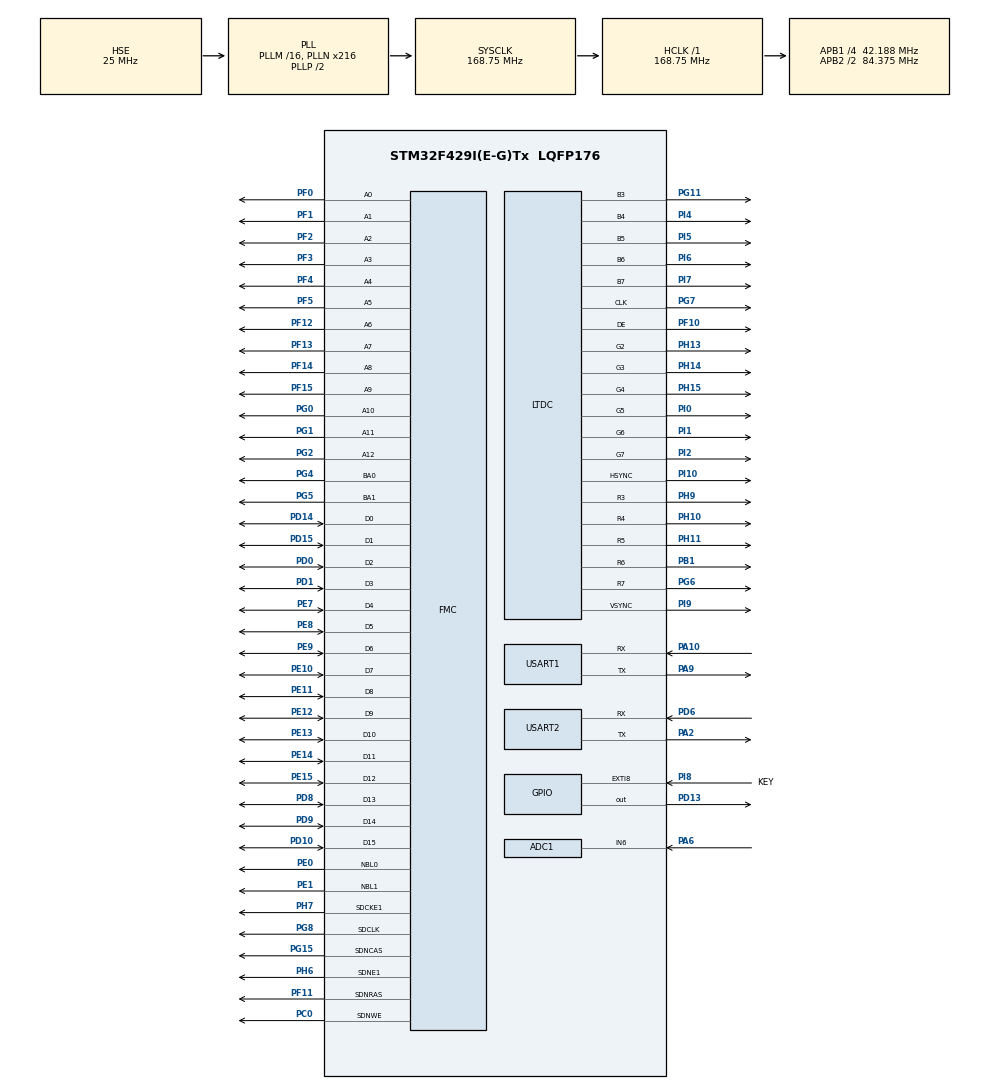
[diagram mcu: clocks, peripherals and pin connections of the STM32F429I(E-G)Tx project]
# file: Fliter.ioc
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ADC1.Channel-3\#ChannelRegularConversion=ADC_CHANNEL_6
ADC1.DMAContinuousRequests=ENABLE
ADC1.EOCSelection=ADC_EOC_SEQ_CONV
ADC1.ExternalTrigConv=ADC_EXTERNALTRIGCONV_T3_TRGO
ADC1.InjNumberOfConversion=0
ADC1.NbrOfConversion=1
ADC1.NbrOfConversionFlag=1
ADC1.Rank-3\#ChannelRegularConversion=1
ADC1.SamplingTime-3\#ChannelRegularConversion=ADC_SAMPLETIME_3CYCLES
ADC1.master=1
DMA2D.ColorMode=DMA2D_OUTPUT_RGB565
DMA2D.Mode=DMA2D_R2M
Dma.ADC1.0.Direction=DMA_PERIPH_TO_MEMORY
Dma.ADC1.0.FIFOMode=DMA_FIFOMODE_DISABLE
Dma.ADC1.0.Instance=DMA2_Stream0
Dma.ADC1.0.MemDataAlignment=DMA_MDATAALIGN_HALFWORD
Dma.ADC1.0.MemInc=DMA_MINC_ENABLE
Dma.ADC1.0.Mode=DMA_NORMAL
Dma.ADC1.0.PeriphDataAlignment=DMA_PDATAALIGN_HALFWORD
Dma.ADC1.0.PeriphInc=DMA_PINC_DISABLE
Dma.ADC1.0.Priority=DMA_PRIORITY_LOW
Dma.Request0=ADC1
FMC.CASLatency2=FMC_SDRAM_CAS_LATENCY_3
FMC.ColumnBitsNumber2=FMC_SDRAM_COLUMN_BITS_NUM_9
FMC.ExitSelfRefreshDelay2=7
FMC.LoadToActiveDelay2=2
FMC.RCDDelay2=2
FMC.RPDelay1=2
FMC.RPDelay2=2
FMC.ReadBurst1=FMC_SDRAM_RBURST_ENABLE
FMC.ReadBurst2=FMC_SDRAM_RBURST_ENABLE
FMC.ReadPipeDelay1=FMC_SDRAM_RPIPE_DELAY_1
FMC.ReadPipeDelay2=FMC_SDRAM_RPIPE_DELAY_1
FMC.RowCycleDelay1=7
FMC.RowCycleDelay2=7
FMC.SDClockPeriod1=FMC_SDRAM_CLOCK_PERIOD_2
FMC.SDClockPeriod2=FMC_SDRAM_CLOCK_PERIOD_2
FMC.SelfRefreshTime2=4
FMC.WriteRecoveryTime2=3
LTDC.ActiveH=272
LTDC.ActiveW=480
LTDC.Alpha_L0=255
LTDC.BlendingFactor1_L0=LTDC_BLENDING_FACTOR1_CA
LTDC.BlendingFactor1_L1=LTDC_BLENDING_FACTOR1_PAxCA
LTDC.BlendingFactor2_L0=LTDC_BLENDING_FACTOR2_CA
LTDC.BlendingFactor2_L1=LTDC_BLENDING_FACTOR2_PAxCA
LTDC.FBStartAdress_L0=0xD0000000
LTDC.FBStartAdress_L1=0xDD000000
LTDC.HBP=43
LTDC.HFP=8
LTDC.HSync=1
LTDC.ImageHeight_L0=272
LTDC.ImageHeight_L1=272
LTDC.ImageWidth_L0=480
LTDC.ImageWidth_L1=480
LTDC.Layers=0
LTDC.PixelFormat_L0=LTDC_PIXEL_FORMAT_RGB565
LTDC.VBP=12
LTDC.VFP=8
LTDC.VSync=1
LTDC.WindowX1_L0=480
LTDC.WindowX1_L1=480
LTDC.WindowY1_L0=272
LTDC.WindowY1_L1=272
Mcu.Family=STM32F4
Mcu.Name=STM32F429I(E-G)Tx
Mcu.Package=LQFP176
NVIC.DMA2D_IRQn=true\:0\:0\:false\:false\:true\:true\:true
NVIC.DMA2_Stream0_IRQn=true\:0\:0\:false\:false\:true\:true\:true
NVIC.EXTI9_5_IRQn=true\:0\:0\:false\:false\:true\:true\:true
NVIC.LTDC_IRQn=true\:0\:0\:false\:false\:true\:true\:true
NVIC.PriorityGroup=NVIC_PRIORITYGROUP_4
PA10.Mode=Asynchronous
PA10.Signal=USART1_RX
PA13.Mode=Serial_Wire
PA13.Signal=SYS_JTMS-SWDIO
PA14.Mode=Serial_Wire
PA14.Signal=SYS_JTCK-SWCLK
PA2.Mode=Asynchronous
PA2.Signal=USART2_TX
PA6.Signal=ADCx_IN6
PA9.Mode=Asynchronous
PA9.Signal=USART1_TX
PB1.GPIO_PuPd=GPIO_NOPULL
PB1.GPIO_Speed=GPIO_SPEED_FREQ_LOW
PB1.Mode=RGB565
PB1.Signal=LTDC_R6
PC0.Signal=FMC_SDNWE
PD0.Signal=FMC_D2_DA2
PD1.Signal=FMC_D3_DA3
PD10.Signal=FMC_D15_DA15
PD13.GPIO_PuPd=GPIO_PULLUP
PD13.PinState=GPIO_PIN_SET
PD13.Signal=GPIO_Output
PD14.Signal=FMC_D0_DA0
PD15.Signal=FMC_D1_DA1
PD6.Mode=Asynchronous
PD6.Signal=USART2_RX
PD8.Signal=FMC_D13_DA13
PD9.Signal=FMC_D14_DA14
PE0.Signal=FMC_NBL0
PE1.Signal=FMC_NBL1
PE10.Signal=FMC_D7_DA7
PE11.Signal=FMC_D8_DA8
PE12.Signal=FMC_D9_DA9
PE13.Signal=FMC_D10_DA10
PE14.Signal=FMC_D11_DA11
PE15.Signal=FMC_D12_DA12
PE7.Signal=FMC_D4_DA4
PE8.Signal=FMC_D5_DA5
PE9.Signal=FMC_D6_DA6
PF0.Signal=FMC_A0
PF1.Signal=FMC_A1
PF10.GPIO_PuPd=GPIO_NOPULL
PF10.GPIO_Speed=GPIO_SPEED_FREQ_LOW
PF10.Mode=RGB565
PF10.Signal=LTDC_DE
PF11.Signal=FMC_SDNRAS
PF12.Signal=FMC_A6
PF13.Signal=FMC_A7
PF14.Signal=FMC_A8
PF15.Signal=FMC_A9
PF2.Signal=FMC_A2
PF3.Signal=FMC_A3
PF4.Signal=FMC_A4
PF5.Signal=FMC_A5
PG0.Signal=FMC_A10
PG1.Signal=FMC_A11
PG11.GPIO_PuPd=GPIO_NOPULL
PG11.GPIO_Speed=GPIO_SPEED_FREQ_LOW
PG11.Mode=RGB565
PG11.Signal=LTDC_B3
PG15.Signal=FMC_SDNCAS
PG2.Signal=FMC_A12
PG4.Signal=FMC_A14_BA0
PG5.Signal=FMC_A15_BA1
PG6.GPIO_PuPd=GPIO_NOPULL
PG6.GPIO_Speed=GPIO_SPEED_FREQ_LOW
PG6.Mode=RGB565
PG6.Signal=LTDC_R7
PG7.GPIO_PuPd=GPIO_NOPULL
PG7.GPIO_Speed=GPIO_SPEED_FREQ_LOW
PG7.Mode=RGB565
PG7.Signal=LTDC_CLK
PG8.Signal=FMC_SDCLK
PH0/OSC_IN.Mode=HSE-External-Oscillator
PH0/OSC_IN.Signal=RCC_OSC_IN
PH1/OSC_OUT.Mode=HSE-External-Oscillator
PH1/OSC_OUT.Signal=RCC_OSC_OUT
PH10.GPIO_PuPd=GPIO_NOPULL
PH10.GPIO_Speed=GPIO_SPEED_FREQ_LOW
PH10.Mode=RGB565
PH10.Signal=LTDC_R4
PH11.GPIO_PuPd=GPIO_NOPULL
PH11.GPIO_Speed=GPIO_SPEED_FREQ_LOW
PH11.Mode=RGB565
PH11.Signal=LTDC_R5
PH13.GPIO_PuPd=GPIO_NOPULL
PH13.GPIO_Speed=GPIO_SPEED_FREQ_LOW
PH13.Mode=RGB565
PH13.Signal=LTDC_G2
PH14.GPIO_PuPd=GPIO_NOPULL
PH14.GPIO_Speed=GPIO_SPEED_FREQ_LOW
PH14.Mode=RGB565
PH14.Signal=LTDC_G3
PH15.GPIO_PuPd=GPIO_NOPULL
PH15.GPIO_Speed=GPIO_SPEED_FREQ_LOW
PH15.Mode=RGB565
PH15.Signal=LTDC_G4
PH6.Mode=SdramChipSelect2_2
PH6.Signal=FMC_SDNE1
PH7.Mode=SdramChipSelect2_2
PH7.Signal=FMC_SDCKE1
PH9.GPIO_PuPd=GPIO_NOPULL
PH9.GPIO_Speed=GPIO_SPEED_FREQ_LOW
PH9.Mode=RGB565
PH9.Signal=LTDC_R3
PI0.GPIO_PuPd=GPIO_NOPULL
PI0.GPIO_Speed=GPIO_SPEED_FREQ_LOW
PI0.Mode=RGB565
PI0.Signal=LTDC_G5
PI1.GPIO_PuPd=GPIO_NOPULL
PI1.GPIO_Speed=GPIO_SPEED_FREQ_LOW
PI1.Mode=RGB565
PI1.Signal=LTDC_G6
PI10.GPIO_PuPd=GPIO_NOPULL
PI10.GPIO_Speed=GPIO_SPEED_FREQ_LOW
PI10.Mode=RGB565
PI10.Signal=LTDC_HSYNC
PI2.GPIO_PuPd=GPIO_NOPULL
PI2.GPIO_Speed=GPIO_SPEED_FREQ_LOW
PI2.Mode=RGB565
PI2.Signal=LTDC_G7
PI4.GPIO_PuPd=GPIO_NOPULL
PI4.GPIO_Speed=GPIO_SPEED_FREQ_LOW
PI4.Mode=RGB565
PI4.Signal=LTDC_B4
PI5.GPIO_PuPd=GPIO_NOPULL
PI5.GPIO_Speed=GPIO_SPEED_FREQ_LOW
PI5.Mode=RGB565
PI5.Signal=LTDC_B5
PI6.GPIO_PuPd=GPIO_NOPULL
PI6.GPIO_Speed=GPIO_SPEED_FREQ_LOW
PI6.Mode=RGB565
PI6.Signal=LTDC_B6
PI7.GPIO_PuPd=GPIO_NOPULL
PI7.GPIO_Speed=GPIO_SPEED_FREQ_LOW
PI7.Mode=RGB565
PI7.Signal=LTDC_B7
PI8.GPIO_Label=KEY
PI8.GPIO_PuPd=GPIO_PULLUP
PI8.Signal=GPXTI8
PI9.GPIO_PuPd=GPIO_NOPULL
PI9.GPIO_Speed=GPIO_SPEED_FREQ_LOW
PI9.Mode=RGB565
PI9.Signal=LTDC_VSYNC
ProjectManager.HeapSize=0x800
ProjectManager.StackSize=0x1200
ProjectManager.TargetToolchain=SW4STM32
RCC.48MHZClocksFreq_Value=84375000
RCC.AHBFreq_Value=168750000
RCC.APB1CLKDivider=RCC_HCLK_DIV4
RCC.APB1Freq_Value=42187500
RCC.APB1TimFreq_Value=84375000
RCC.APB2CLKDivider=RCC_HCLK_DIV2
RCC.APB2Freq_Value=84375000
RCC.APB2TimFreq_Value=168750000
RCC.CortexFreq_Value=168750000
RCC.HCLKFreq_Value=168750000
RCC.HSE_VALUE=25000000
RCC.HSI_VALUE=16000000
RCC.LSE_VALUE=32768
RCC.PLLN=216
RCC.PLLSAIDivR=RCC_PLLSAIDIVR_4
RCC.PLLSAIN=180
RCC.PLLSAIR=6
RCC.PLLSourceVirtual=RCC_PLLSOURCE_HSE
RCC.SYSCLKFreq_VALUE=168750000
RCC.SYSCLKSource=RCC_SYSCLKSOURCE_PLLCLK
RCC.VCOOutputFreq_Value=337500000
SH.ADCx_IN6.0=ADC1_IN6,IN6
SH.FMC_A0.0=FMC_A0,13b-sda2
SH.FMC_A1.0=FMC_A1,13b-sda2
SH.FMC_A10.0=FMC_A10,13b-sda2
SH.FMC_A11.0=FMC_A11,13b-sda2
SH.FMC_A12.0=FMC_A12,13b-sda2
SH.FMC_A14_BA0.0=FMC_BA0,FourSdramBanks2
SH.FMC_A15_BA1.0=FMC_BA1,FourSdramBanks2
SH.FMC_A2.0=FMC_A2,13b-sda2
SH.FMC_A3.0=FMC_A3,13b-sda2
SH.FMC_A4.0=FMC_A4,13b-sda2
SH.FMC_A5.0=FMC_A5,13b-sda2
SH.FMC_A6.0=FMC_A6,13b-sda2
SH.FMC_A7.0=FMC_A7,13b-sda2
SH.FMC_A8.0=FMC_A8,13b-sda2
SH.FMC_A9.0=FMC_A9,13b-sda2
SH.FMC_D0_DA0.0=FMC_D0,sd-16b-d2
SH.FMC_D10_DA10.0=FMC_D10,sd-16b-d2
SH.FMC_D11_DA11.0=FMC_D11,sd-16b-d2
SH.FMC_D12_DA12.0=FMC_D12,sd-16b-d2
SH.FMC_D13_DA13.0=FMC_D13,sd-16b-d2
SH.FMC_D14_DA14.0=FMC_D14,sd-16b-d2
SH.FMC_D15_DA15.0=FMC_D15,sd-16b-d2
SH.FMC_D1_DA1.0=FMC_D1,sd-16b-d2
SH.FMC_D2_DA2.0=FMC_D2,sd-16b-d2
SH.FMC_D3_DA3.0=FMC_D3,sd-16b-d2
SH.FMC_D4_DA4.0=FMC_D4,sd-16b-d2
SH.FMC_D5_DA5.0=FMC_D5,sd-16b-d2
SH.FMC_D6_DA6.0=FMC_D6,sd-16b-d2
SH.FMC_D7_DA7.0=FMC_D7,sd-16b-d2
SH.FMC_D8_DA8.0=FMC_D8,sd-16b-d2
SH.FMC_D9_DA9.0=FMC_D9,sd-16b-d2
SH.FMC_NBL0.0=FMC_NBL0,Sd2ByteEnable2
SH.FMC_NBL1.0=FMC_NBL1,Sd2ByteEnable2
SH.FMC_SDCLK.0=FMC_SDCLK,13b-sda2
SH.FMC_SDNCAS.0=FMC_SDNCAS,13b-sda2
SH.FMC_SDNRAS.0=FMC_SDNRAS,13b-sda2
SH.FMC_SDNWE.0=FMC_SDNWE,13b-sda2
STMicroelectronics.X-CUBE-ALGOBUILD.1.2.1.LibraryCcDSPOoLibraryJjDSPOoLibrary=true
TIM3.AutoReloadPreload=TIM_AUTORELOAD_PRELOAD_ENABLE
TIM3.Period=9-1
TIM3.Prescaler=9-1
TIM3.TIM_MasterOutputTrigger=TIM_TRGO_UPDATE
USART1.VirtualMode=VM_ASYNC
USART2.VirtualMode=VM_ASYNC
VP_DMA2D_VS_DMA2D.Mode=DMA2D_Activate
VP_STMicroelectronics.X-CUBE-ALGOBUILD_VS_DSPOoLibraryJjLibrary_1.2.1_1.2.1.Mode=DSPOoLibraryJjLibrary
VP_TIM3_VS_ClockSourceINT.Mode=Internal
board=custom

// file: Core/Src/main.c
/* USER CODE BEGIN Header */
/**
  ******************************************************************************
  * @file           : main.c
  * @brief          : Main program body
  ******************************************************************************
  * @attention
  *
  * <h2><center>&copy; Copyright (c) 2021 STMicroelectronics.
  * All rights reserved.</center></h2>
  *
  * This software component is licensed by ST under BSD 3-Clause license,
  * the "License"; You may not use this file except in compliance with the
  * License. You may obtain a copy of the License at:
  *                        opensource.org/licenses/BSD-3-Clause
  *
  ******************************************************************************
  */
/* USER CODE END Header */
#include "main.h"
#include "adc.h"
#include "dma.h"
#include "dma2d.h"
#include "ltdc.h"
#include "tim.h"
#include "usart.h"
#include "gpio.h"
#include "fmc.h"

/* USER CODE BEGIN Includes */
#include "arm_math.h"
#include "stdio.h"
#include "stdarg.h"
#include "window.h"
#include "math.h"
/* USER CODE END Includes */

/* USER CODE BEGIN PV */
axishander axis;
uint16_t sampleCplt = 0;
arm_rfft_fast_instance_f32 fftIns;

uint16_t adcBuf[2048];
float32_t fftIn[2048], fftOut[2048];
float32_t amplFreq[1024];
uint32_t freqDst[5];
float32_t amplDst[5], normalAmplDst[5];
float32_t THDx = 0.0;
float phase[5] = {};
float32_t RMS[5];
/* USER CODE END PV */

void SystemClock_Config(void);

int main(void)
{

  /* MCU Configuration--------------------------------------------------------*/

  /* Reset of all peripherals, Initializes the Flash interface and the Systick. */
  HAL_Init();

  /* Configure the system clock */
  SystemClock_Config();

  /* Initialize all configured peripherals */
  MX_GPIO_Init();
  MX_USART1_UART_Init();
  MX_USART2_UART_Init();
  MX_FMC_Init();
  MX_LTDC_Init();
  MX_DMA_Init();
  MX_ADC1_Init();
  MX_DMA2D_Init();
  MX_TIM3_Init();
  /* USER CODE BEGIN 2 */

    WinInit(&axis, 0, 136, 23);
    LIB_RFFT_Init();
    LCD_Clear();
    HAL_ADC_Start_DMA(&hadc1, (uint32_t *) adcBuf, 2048);
  /* USER CODE END 2 */

  /* Infinite loop */
    while (1) {

    /* USER CODE BEGIN 3 */
        if (LIB_RFFT_Process()) {
            HAL_Delay(1000);
            HAL_ADC_Start_DMA(&hadc1, (uint32_t *) adcBuf, 2048);
            Packageup(fftIn, THDx, normalAmplDst);
        }

        /*TODO:*//*HAL_UART_*/
    }
  /* USER CODE END 3 */
}

void SystemClock_Config(void)
{
  RCC_OscInitTypeDef RCC_OscInitStruct = {0};
  RCC_ClkInitTypeDef RCC_ClkInitStruct = {0};

  /** Configure the main internal regulator output voltage
  */
  __HAL_RCC_PWR_CLK_ENABLE();
  __HAL_PWR_VOLTAGESCALING_CONFIG(PWR_REGULATOR_VOLTAGE_SCALE1);
  /** Initializes the RCC Oscillators according to the specified parameters
  * in the RCC_OscInitTypeDef structure.
  */
  RCC_OscInitStruct.OscillatorType = RCC_OSCILLATORTYPE_HSE;
  RCC_OscInitStruct.HSEState = RCC_HSE_ON;
  RCC_OscInitStruct.PLL.PLLState = RCC_PLL_ON;
  RCC_OscInitStruct.PLL.PLLSource = RCC_PLLSOURCE_HSE;
  RCC_OscInitStruct.PLL.PLLM = 16;
  RCC_OscInitStruct.PLL.PLLN = 216;
  RCC_OscInitStruct.PLL.PLLP = RCC_PLLP_DIV2;
  RCC_OscInitStruct.PLL.PLLQ = 4;
  if (HAL_RCC_OscConfig(&RCC_OscInitStruct) != HAL_OK)
  {
    Error_Handler();
  }
  /** Activate the Over-Drive mode
  */
  if (HAL_PWREx_EnableOverDrive() != HAL_OK)
  {
    Error_Handler();
  }
  /** Initializes the CPU, AHB and APB buses clocks
  */
  RCC_ClkInitStruct.ClockType = RCC_CLOCKTYPE_HCLK|RCC_CLOCKTYPE_SYSCLK
                              |RCC_CLOCKTYPE_PCLK1|RCC_CLOCKTYPE_PCLK2;
  RCC_ClkInitStruct.SYSCLKSource = RCC_SYSCLKSOURCE_PLLCLK;
  RCC_ClkInitStruct.AHBCLKDivider = RCC_SYSCLK_DIV1;
  RCC_ClkInitStruct.APB1CLKDivider = RCC_HCLK_DIV4;
  RCC_ClkInitStruct.APB2CLKDivider = RCC_HCLK_DIV2;

  if (HAL_RCC_ClockConfig(&RCC_ClkInitStruct, FLASH_LATENCY_5) != HAL_OK)
  {
    Error_Handler();
  }
}

/* USER CODE BEGIN 4 */

void HAL_ADC_ConvCpltCallback(ADC_HandleTypeDef *hadc) {
    if (&hadc1 == hadc) {
        sampleCplt = 1;
        for (int i = 0; i < fftIns.fftLenRFFT; ++i) {
            fftIn[i] = adcBuf[i] * 3.3 / 4096.0;
        }

/*        printf("hello\r\n");
        for (int i = 0; i < 2048; ++i) {
            printf("%d\r\n", adcBuf[i]);
        }*/
    }
}

void LIB_RFFT_Init() {
    arm_rfft_fast_init_f32(&fftIns, 2048);
    sampleCplt = 0;
    HAL_TIM_Base_Start(&htim3);
}

uint8_t LIB_RFFT_Process() {
    if (sampleCplt == 1) {
        uint32_t offset = 0;
        float32_t th;
        uint32_t domain;
        uint32_t limit;

        arm_rfft_fast_f32(&fftIns, fftIn, fftOut, 0);
        arm_cmplx_mag_f32(fftOut, amplFreq, fftIns.fftLenRFFT / 2);

        arm_max_f32(amplFreq + 1, fftIns.fftLenRFFT / 2 - 1, amplDst, freqDst);
        ++freqDst[0];
        phase[0] = atan2(fftOut[freqDst[0] * 2 + 1], fftOut[freqDst[0] * 2]);

        //flush
        amplFreq[0] = 0.0;
        th = amplDst[0] / 100.0;
        for (int i = 1; i < fftIns.fftLenRFFT / 2; ++i) {
            if (amplFreq[i] < th) {
                amplFreq[i] = 0.0;
            }
        }

        offset = sqrt(freqDst[0]);
        for (int i = 1; i < 5; ++i) {
            arm_max_f32(amplFreq + freqDst[0] * (i + 1) - offset,
                        offset * 2 + 1,
                        amplDst + i,
                        freqDst + i);
            freqDst[i] += freqDst[0] * (i + 1) - offset;
            phase[i] = atan2(fftOut[freqDst[i] * 2 + 1], fftOut[freqDst[i] * 2]);
        }

        //rms
        domain = freqDst[0] / 4;
        for (int i = 0; i < 4; ++i) {
            arm_power_f32(amplFreq + freqDst[i] - domain, domain * 2 + 1, RMS + i);
            RMS[i] = sqrt(RMS[i]);
            normalAmplDst[i] = RMS[i] / RMS[0];
        }
        limit = fftIns.fftLenRFFT / 2 - (freqDst[4] - domain) - 1;
        limit = limit < (domain * 2 + 1) ? limit : (2 * domain + 1);
        arm_power_f32(amplFreq + freqDst[4] - domain, limit, RMS + 4);
        RMS[4] = sqrt(RMS[4]);
        normalAmplDst[4] = RMS[4] / RMS[0];

        THDx = sqrt(pow(normalAmplDst[1], 2) + pow(normalAmplDst[2], 2) + pow(normalAmplDst[3], 2) + pow(normalAmplDst[4], 2));
        Painting(&axis, fftIn, freqDst, phase, THDx, normalAmplDst);
        sampleCplt = 0;
        return 1;
    }
    return 0;
}

/* USER CODE END 4 */

void Error_Handler(void)
{
    __disable_irq();
    while (1) {
    }
}

/************************ (C) COPYRIGHT STMicroelectronics *****END OF FILE****/
